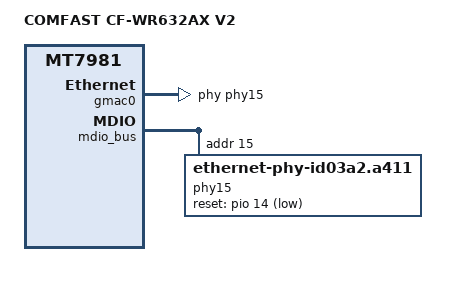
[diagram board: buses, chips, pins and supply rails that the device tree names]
// SPDX-License-Identifier: GPL-2.0-or-later OR MIT

#include "mt7981b-comfast-cf-wr632ax-common.dtsi"

/ {
	model = "COMFAST CF-WR632AX V2";
	compatible = "comfast,cf-wr632ax-v2", "mediatek,mt7981";
};

&gmac0 {
	phy-handle = <&phy15>;
};

&mdio_bus {
	/delete-property/ reset-gpios;
	/delete-property/ reset-delay-us;
	/delete-property/ reset-post-delay-us;

	/delete-node/ phy@5;

	phy15: phy@f {
		compatible = "ethernet-phy-id03a2.a411";
		reg = <15>;

		reset-gpios = <&pio 14 GPIO_ACTIVE_LOW>;
		reset-assert-us = <10000>;
		reset-deassert-us = <10000>;
	};
};

&spi_nand {
	mediatek,nmbm;
	mediatek,bmt-max-ratio = <1>;
	mediatek,bmt-max-reserved-blocks = <64>;
	mediatek,bmt-mtd-overridden-oobsize = <64>;
};

&ubi {
	reg = <0x580000 0x4000000>;
};
